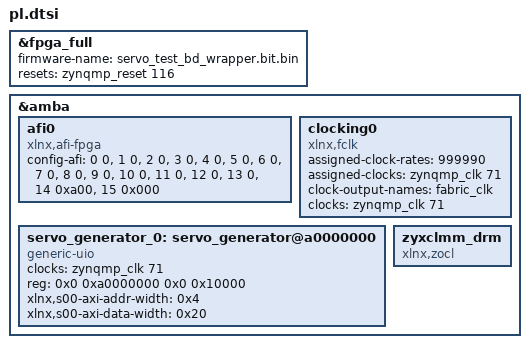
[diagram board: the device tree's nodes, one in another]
/*
 * CAUTION: This file is automatically generated by Xilinx.
 * Version: XSCT 
 * Today is: Tue Apr  8 15:46:43 2025
 */


/dts-v1/;
/plugin/;
/ {
	fragment@0 {
		target = <&fpga_full>;
		overlay0: __overlay__ {
			#address-cells = <2>;
			#size-cells = <2>;
			firmware-name = "servo_test_bd_wrapper.bit.bin";
			resets = <&zynqmp_reset 116>;
		};
	};
	fragment@1 {
		target = <&amba>;
		overlay1: __overlay__ {
			afi0: afi0 {
				compatible = "xlnx,afi-fpga";
				config-afi = < 0 0>, <1 0>, <2 0>, <3 0>, <4 0>, <5 0>, <6 0>, <7 0>, <8 0>, <9 0>, <10 0>, <11 0>, <12 0>, <13 0>, <14 0xa00>, <15 0x000>;
			};
			clocking0: clocking0 {
				#clock-cells = <0>;
				assigned-clock-rates = <999990>;
				assigned-clocks = <&zynqmp_clk 71>;
				clock-output-names = "fabric_clk";
				clocks = <&zynqmp_clk 71>;
				compatible = "xlnx,fclk";
			};
		};
	};
	fragment@2 {
		target = <&amba>;
		overlay2: __overlay__ {
			#address-cells = <2>;
			#size-cells = <2>;
			servo_generator_0: servo_generator@a0000000 {
				clock-names = "s00_axi_aclk";
				clocks = <&zynqmp_clk 71>;
				compatible = "generic-uio";
				reg = <0x0 0xa0000000 0x0 0x10000>;
				xlnx,s00-axi-addr-width = <0x4>;
				xlnx,s00-axi-data-width = <0x20>;
			};
			zyxclmm_drm {
				compatible = "xlnx,zocl";
			};
		};
	};
};
